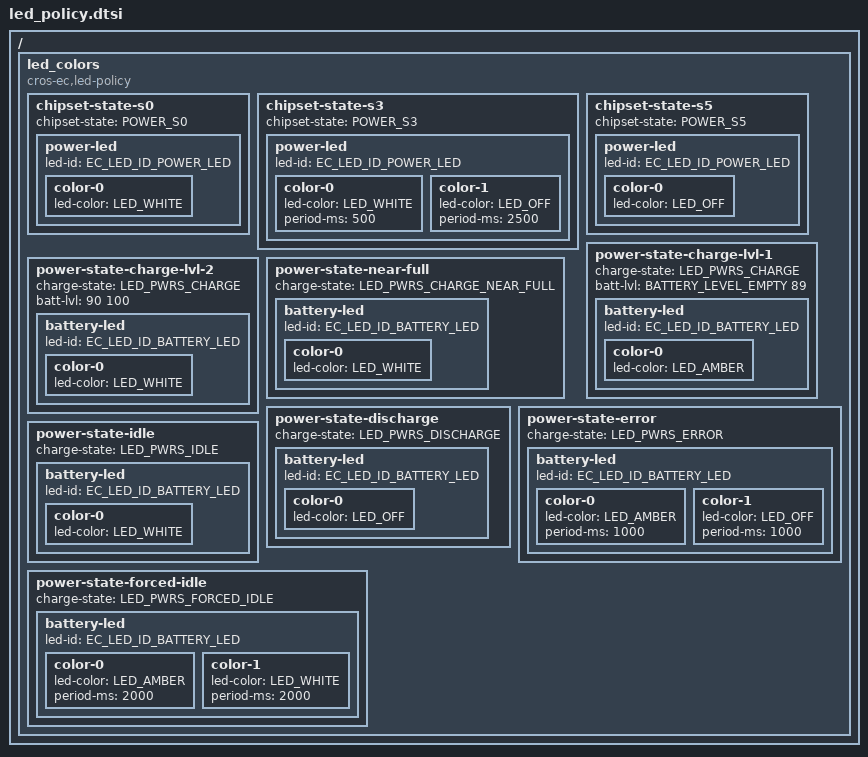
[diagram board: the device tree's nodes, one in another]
/* Copyright 2026 The ChromiumOS Authors
 * Use of this source code is governed by a BSD-style license that can be
 * found in the LICENSE file.
 */

#include <dt-bindings/battery.h>

/ {

	led_colors {
		compatible = "cros-ec,led-policy";

		chipset-state-s0 {
			chipset-state = "POWER_S0";

			power-led {
				led-id = "EC_LED_ID_POWER_LED";

				color-0 {
					led-color = "LED_WHITE";
				};
			};
		};

		chipset-state-s3 {
			chipset-state = "POWER_S3";

			power-led {
				led-id = "EC_LED_ID_POWER_LED";

				color-0 {
					led-color = "LED_WHITE";
					period-ms = <500>;
				};

				color-1 {
					led-color = "LED_OFF";
					period-ms = <2500>;
				};
			};
		};

		chipset-state-s5 {
			chipset-state = "POWER_S5";

			power-led {
				led-id = "EC_LED_ID_POWER_LED";
				color-0 {
					led-color = "LED_OFF";
				};
			};
		};

		power-state-charge-lvl-1 {
			charge-state = "LED_PWRS_CHARGE";
			/* Battery display percent range (>= 0, <= 89%) */
			batt-lvl = <BATTERY_LEVEL_EMPTY 89>;

			battery-led {
				led-id = "EC_LED_ID_BATTERY_LED";
				color-0 {
					led-color = "LED_AMBER";
				};
			};
		};

		power-state-charge-lvl-2 {
			charge-state = "LED_PWRS_CHARGE";
			/* Battery display percent range (>= 90, <= 100) */
			batt-lvl = <90 100>;

			battery-led {
				led-id = "EC_LED_ID_BATTERY_LED";
				color-0 {
					led-color = "LED_WHITE";
				};
			};
		};

		power-state-near-full {
			charge-state = "LED_PWRS_CHARGE_NEAR_FULL";

			battery-led {
				led-id = "EC_LED_ID_BATTERY_LED";
				color-0 {
					led-color = "LED_WHITE";
				};
			};
		};

		power-state-discharge {
			charge-state = "LED_PWRS_DISCHARGE";

			battery-led {
				led-id = "EC_LED_ID_BATTERY_LED";
				color-0 {
					led-color = "LED_OFF";
				};
			};
		};

		power-state-error {
			charge-state = "LED_PWRS_ERROR";

			battery-led {
				led-id = "EC_LED_ID_BATTERY_LED";
				color-0 {
					led-color = "LED_AMBER";
					period-ms = <1000>;
				};
				color-1 {
					led-color = "LED_OFF";
					period-ms = <1000>;
				};
			};
		};

		power-state-idle {
			charge-state = "LED_PWRS_IDLE";

			battery-led {
				led-id = "EC_LED_ID_BATTERY_LED";
				color-0 {
					led-color = "LED_WHITE";
				};
			};
		};

		power-state-forced-idle {
			charge-state = "LED_PWRS_FORCED_IDLE";

			battery-led {
				led-id = "EC_LED_ID_BATTERY_LED";
				color-0 {
					led-color = "LED_AMBER";
					period-ms = <2000>;
				};
				color-1 {
					led-color = "LED_WHITE";
					period-ms = <2000>;
				};
			};
		};
	};
};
